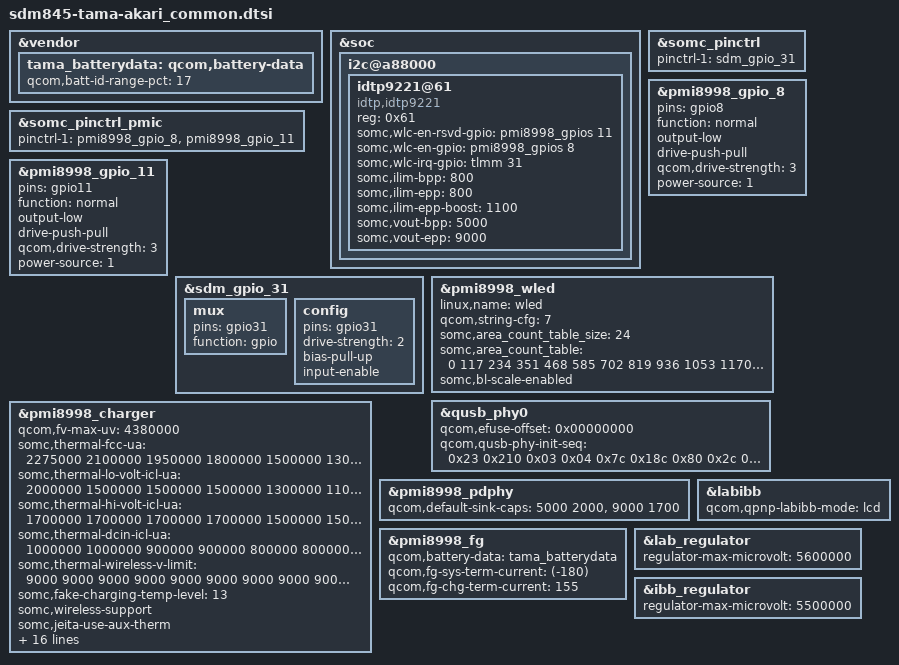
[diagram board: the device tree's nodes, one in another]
/* arch/arm64/boot/dts/somc/sdm845-tama-akari_common.dtsi
 *
 * This program is free software; you can redistribute it and/or modify
 * it under the terms of the GNU General Public License version 2 and
 * only version 2 as published by the Free Software Foundation.
 *
 * This program is distributed in the hope that it will be useful,
 * but WITHOUT ANY WARRANTY; without even the implied warranty of
 * MERCHANTABILITY or FITNESS FOR A PARTICULAR PURPOSE.  See the
 * GNU General Public License for more details.
 */
/*
 * Copyright (C) 2017 Sony Mobile Communications Inc.
 *
 * This program is free software; you can redistribute it and/or modify
 * it under the terms of the GNU General Public License version 2, as
 * published by the Free Software Foundation.
 */

#include "sdm845-tama-common.dtsi"
#include "sdm845-tama-common-display.dtsi"
#include "sdm845-tama-akari-camera.dtsi"
#include "dsi-panel-somc-akari.dtsi"

&vendor {
	tama_batterydata: qcom,battery-data {
		qcom,batt-id-range-pct = <17>;
		#include "fg-gen3-batterydata-akari-tmm-4380mv.dtsi"
		#include "fg-gen3-batterydata-akari-tmm-4340mv.dtsi"
		#include "fg-gen3-batterydata-akari-tmm-4300mv.dtsi"
		#include "fg-gen3-batterydata-akari-tmm-4250mv.dtsi"
		#include "fg-gen3-batterydata-akari-byd-4380mv.dtsi"
		#include "fg-gen3-batterydata-akari-byd-4340mv.dtsi"
		#include "fg-gen3-batterydata-akari-byd-4300mv.dtsi"
		#include "fg-gen3-batterydata-akari-byd-4250mv.dtsi"
	};
};

&soc {
	/* I2C: QUP10 - WLC */
	i2c@a88000 {
		idtp9221@61 {
			compatible = "idtp,idtp9221";
			reg = <0x61>;
			status = "ok";
			somc,wlc-en-rsvd-gpio = <&pmi8998_gpios 11 0>;
			somc,wlc-en-gpio = <&pmi8998_gpios 8 0>;
			somc,wlc-irq-gpio = <&tlmm 31 0>;
			somc,ilim-bpp = <800>;
			somc,ilim-epp = <800>;
			somc,ilim-epp-boost = <1100>;
			somc,vout-bpp = <5000>;
			somc,vout-epp = <9000>;
		};
	};

};

&somc_pinctrl {
	/* If product common default setting is needed,
	fill pinctrl-1 value in <product>_common.dtsi */
	pinctrl-1 = <&sdm_gpio_31>;
};

&somc_pinctrl_pmic {
	/* If product common PMIC default setting is needed,
	fill pinctrl-1 value in <product>_common.dtsi */
	pinctrl-1 = <&pmi8998_gpio_8 &pmi8998_gpio_11>;
};

/* GPIO_8: WLC_EN_N */
&pmi8998_gpio_8 {
	pins = "gpio8";
	function = "normal";
	/delete-property/ bias-high-impedance;
	output-low;
	drive-push-pull;
	qcom,drive-strength = <3>;
	power-source = <1>;
};

/* GPIO_11: RSVD(WLC_EN_N) */
&pmi8998_gpio_11 {
	pins = "gpio11";
	function = "normal";
	/delete-property/ bias-high-impedance;
	output-low;
	drive-push-pull;
	qcom,drive-strength = <3>;
	power-source = <1>;
};

/* GPIO_31 : WLC_INT_N */
&sdm_gpio_31 {
	mux {
		pins = "gpio31";
		function = "gpio";
	};
	config {
		pins = "gpio31";
		drive-strength = <2>;
		/delete-property/ bias-pull-down;
		bias-pull-up;
		input-enable;
	};
};

&pmi8998_wled {
	linux,name = "wled";
	qcom,string-cfg = <7>;
	somc,area_count_table_size = <24>;
	somc,area_count_table = <0 117 234 351 468 585 702 819
				936 1053 1170 1404 1638 1872 2106
				2340 2574 2808 3042 3276 3510
				3744 3978 4095>;
	somc,bl-scale-enabled;
};

&qusb_phy0 {
	qcom,efuse-offset = <0x00000000>;
	qcom,qusb-phy-init-seq =
		/* <value reg_offset> */
		   <0x23 0x210 /* PWR_CTRL1 */
		    0x03 0x04  /* PLL_ANALOG_CONTROLS_TWO */
		    0x7c 0x18c /* PLL_CLOCK_INVERTERS */
		    0x80 0x2c  /* PLL_CMODE */
		    0x0a 0x184 /* PLL_LOCK_DELAY */
		    0x19 0xb4  /* PLL_DIGITAL_TIMERS_TWO */
		    0x40 0x194 /* PLL_BIAS_CONTROL_1 */
		    0x16 0x198 /* PLL_BIAS_CONTROL_2 */
		    0x21 0x214 /* PWR_CTRL2 */
		    0x08 0x220 /* IMP_CTRL1 */
		    0x58 0x224 /* IMP_CTRL2 */
		    0x75 0x240 /* TUNE1 */
		    0x2B 0x244 /* TUNE2 */
		    0xca 0x248 /* TUNE3 */
		    0x04 0x24c /* TUNE4 */
		    0x01 0x250 /* TUNE5 */
		    0x00 0x23c /* CHG_CTRL2 */
		    0x22 0x210>; /* PWR_CTRL1 */
};

&pmi8998_charger {
	qcom,fv-max-uv = <4380000>;
	somc,thermal-fcc-ua = <2275000 2100000 1950000
				1800000 1500000 1300000
				1300000 1000000 800000
				700000 500000 200000
				100000 0 0>;
	somc,thermal-lo-volt-icl-ua = <2000000 1500000 1500000
					1500000 1300000 1100000
					1100000 1000000 900000
					900000 500000 200000
					100000 0 0>;
	somc,thermal-hi-volt-icl-ua = <1700000 1700000 1700000
					1700000 1500000 1500000
					1000000 1000000 1000000
					600000 500000 200000
					100000 0 0>;
	somc,thermal-dcin-icl-ua = <1000000 1000000 900000
					900000 800000 800000
					700000 600000 500000
					400000 300000 200000
					100000 0 0>;
	somc,thermal-wireless-v-limit = <9000 9000 9000
					9000 9000 9000
					9000 9000 9000
					9000 5000 5000
					5000 5000 5000>;
	somc,fake-charging-temp-level = <13>;
	somc,wireless-support;
	somc,jeita-use-aux-therm;
	somc,jeita-use-wlc-therm;
	somc,jeita-aux-thresh-hot = <900>;
	somc,jeita-aux-thresh-warm = <700>;
	somc,jeita-wlc-thresh-hot = <580>;
	somc,jeita-wlc-thresh-warm = <480>;
	somc,jeita-warm-fcc-ua = <900000>;
	somc,jeita-cool-fcc-ua = <900000>;
	somc,jeita-warm-fv-uv = <4147000>;
	somc,product-icl-ua = <2000000>;
	somc,high-voltage-icl-ua = <1700000>;
	qcom,dc-icl-ua = <1000000>;
	somc,dc-h-volt-boost-icl-ua = <1000000>;
	somc,dc-h-volt-icl-ua = <700000>;
	somc,dc-l-volt-icl-ua = <700000>;
	somc,batt-temp-correction = <0>;
	somc,wlc-temp-correction = <(-30)>;
};

&pmi8998_pdphy {
	qcom,default-sink-caps = <5000 2000>, /* 5V @ 2A */
				 <9000 1700>; /* 9V @ 1.7A */
};

&pmi8998_fg {
	qcom,battery-data = <&tama_batterydata>;
	qcom,fg-sys-term-current = <(-180)>;
	qcom,fg-chg-term-current = <155>;
};

&labibb {
	qcom,qpnp-labibb-mode = "lcd";
};

&lab_regulator {
	regulator-max-microvolt = <5600000>;
};

&ibb_regulator {
	regulator-max-microvolt = <5500000>;
};
